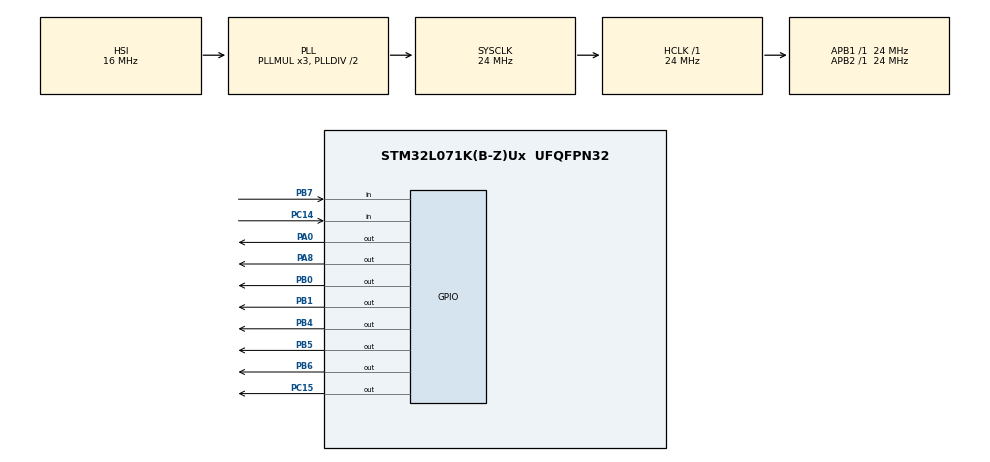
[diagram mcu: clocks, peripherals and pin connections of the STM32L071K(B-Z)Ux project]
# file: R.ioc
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Mcu.Family=STM32L0
Mcu.Name=STM32L071K(B-Z)Ux
Mcu.Package=UFQFPN32
PA0.GPIO_PuPd=GPIO_PULLDOWN
PA0.PinState=GPIO_PIN_RESET
PA0.Signal=GPIO_Output
PA8.Signal=GPIO_Output
PB0.Signal=GPIO_Output
PB1.Signal=GPIO_Output
PB4.Signal=GPIO_Output
PB5.Signal=GPIO_Output
PB6.Signal=GPIO_Output
PB7.Signal=GPIO_Input
PC14-OSC32_IN.Signal=GPIO_Input
PC15-OSC32_OUT.Signal=GPIO_Output
ProjectManager.HeapSize=0x200
ProjectManager.StackSize=0x400
ProjectManager.TargetToolchain=MDK-ARM V5
RCC.AHBFreq_Value=24000000
RCC.APB1Freq_Value=24000000
RCC.APB1TimFreq_Value=24000000
RCC.APB2Freq_Value=24000000
RCC.APB2TimFreq_Value=24000000
RCC.HCLKFreq_Value=24000000
RCC.HSI16_VALUE=16000000
RCC.HSI_VALUE=16000000
RCC.LSE_VALUE=32768
RCC.MSI_VALUE=2097000
RCC.SYSCLKFreq_VALUE=24000000
RCC.SYSCLKSource=RCC_SYSCLKSOURCE_PLLCLK
RCC.VCOOutputFreq_Value=48000000
RTC.Date=10
RTC.Format=RTC_FORMAT_BIN
RTC.Hours=10
RTC.Minutes=10
RTC.Month=RTC_MONTH_OCTOBER
RTC.Seconds=10
RTC.WeekDay=RTC_WEEKDAY_WEDNESDAY
RTC.Year=1
VP_RTC_VS_RTC_Activate.Mode=RTC_Enabled
VP_RTC_VS_RTC_Calendar.Mode=RTC_Calendar
board=custom

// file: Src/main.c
/* USER CODE BEGIN Header */
/**
  ******************************************************************************
  * @file           : main.c
  * @brief          : Main program body
  ******************************************************************************
  * @attention
  *
  * <h2><center>&copy; Copyright (c) 2019 STMicroelectronics.
  * All rights reserved.</center></h2>
  *
  * This software component is licensed by ST under BSD 3-Clause license,
  * the "License"; You may not use this file except in compliance with the
  * License. You may obtain a copy of the License at:
  *                        opensource.org/licenses/BSD-3-Clause
  *
  ******************************************************************************
  */
/* USER CODE END Header */

#include "main.h"

RTC_HandleTypeDef hrtc;

void SystemClock_Config(void);
static void MX_GPIO_Init(void);
static void MX_RTC_Init(void);

int main(void)
{

    /* MCU Configuration--------------------------------------------------------*/

    /* Reset of all peripherals, Initializes the Flash interface and the Systick. */
    HAL_Init();

    /* Configure the system clock */
    SystemClock_Config();

    /* Initialize all configured peripherals */
    MX_GPIO_Init();
    MX_RTC_Init();
    /* USER CODE BEGIN 2 */
    Task_BrdInit();

    /* USER CODE END 2 */

    /* Infinite loop */
    while (1)
    {

        /* USER CODE BEGIN 3 */
        Task_Main();
    }
    /* USER CODE END 3 */
}

void SystemClock_Config(void)
{
    RCC_OscInitTypeDef RCC_OscInitStruct = {0};
    RCC_ClkInitTypeDef RCC_ClkInitStruct = {0};
    RCC_PeriphCLKInitTypeDef PeriphClkInit = {0};

    /** Configure the main internal regulator output voltage
    */
    __HAL_PWR_VOLTAGESCALING_CONFIG(PWR_REGULATOR_VOLTAGE_SCALE1);
    /** Initializes the CPU, AHB and APB busses clocks
    */
    RCC_OscInitStruct.OscillatorType = RCC_OSCILLATORTYPE_HSI | RCC_OSCILLATORTYPE_LSI;
    RCC_OscInitStruct.HSIState = RCC_HSI_ON;
    RCC_OscInitStruct.HSICalibrationValue = RCC_HSICALIBRATION_DEFAULT;
    RCC_OscInitStruct.LSIState = RCC_LSI_ON;
    RCC_OscInitStruct.PLL.PLLState = RCC_PLL_ON;
    RCC_OscInitStruct.PLL.PLLSource = RCC_PLLSOURCE_HSI;
    RCC_OscInitStruct.PLL.PLLMUL = RCC_PLLMUL_3;
    RCC_OscInitStruct.PLL.PLLDIV = RCC_PLLDIV_2;
    if (HAL_RCC_OscConfig(&RCC_OscInitStruct) != HAL_OK)
    {
        Error_Handler();
    }
    /** Initializes the CPU, AHB and APB busses clocks
    */
    RCC_ClkInitStruct.ClockType = RCC_CLOCKTYPE_HCLK | RCC_CLOCKTYPE_SYSCLK
                                  | RCC_CLOCKTYPE_PCLK1 | RCC_CLOCKTYPE_PCLK2;
    RCC_ClkInitStruct.SYSCLKSource = RCC_SYSCLKSOURCE_PLLCLK;
    RCC_ClkInitStruct.AHBCLKDivider = RCC_SYSCLK_DIV1;
    RCC_ClkInitStruct.APB1CLKDivider = RCC_HCLK_DIV1;
    RCC_ClkInitStruct.APB2CLKDivider = RCC_HCLK_DIV1;

    if (HAL_RCC_ClockConfig(&RCC_ClkInitStruct, FLASH_LATENCY_1) != HAL_OK)
    {
        Error_Handler();
    }
    PeriphClkInit.PeriphClockSelection = RCC_PERIPHCLK_RTC;
    PeriphClkInit.RTCClockSelection = RCC_RTCCLKSOURCE_LSI;
    if (HAL_RCCEx_PeriphCLKConfig(&PeriphClkInit) != HAL_OK)
    {
        Error_Handler();
    }
}

static void MX_RTC_Init(void)
{

    RTC_TimeTypeDef sTime = {0};
    RTC_DateTypeDef sDate = {0};

    /** Initialize RTC Only
    */
    hrtc.Instance = RTC;
    hrtc.Init.HourFormat = RTC_HOURFORMAT_24;
    hrtc.Init.AsynchPrediv = 127;
    hrtc.Init.SynchPrediv = 255;
    hrtc.Init.OutPut = RTC_OUTPUT_DISABLE;
    hrtc.Init.OutPutRemap = RTC_OUTPUT_REMAP_NONE;
    hrtc.Init.OutPutPolarity = RTC_OUTPUT_POLARITY_HIGH;
    hrtc.Init.OutPutType = RTC_OUTPUT_TYPE_OPENDRAIN;
    if (HAL_RTC_Init(&hrtc) != HAL_OK)
    {
        Error_Handler();
    }

    /** Initialize RTC and set the Time and Date
    */
    sTime.Hours = 10;
    sTime.Minutes = 10;
    sTime.Seconds = 10;
    sTime.DayLightSaving = RTC_DAYLIGHTSAVING_NONE;
    sTime.StoreOperation = RTC_STOREOPERATION_RESET;
    if (HAL_RTC_SetTime(&hrtc, &sTime, RTC_FORMAT_BIN) != HAL_OK)
    {
        Error_Handler();
    }
    sDate.WeekDay = RTC_WEEKDAY_WEDNESDAY;
    sDate.Month = RTC_MONTH_OCTOBER;
    sDate.Date = 10;
    sDate.Year = 1;

    if (HAL_RTC_SetDate(&hrtc, &sDate, RTC_FORMAT_BIN) != HAL_OK)
    {
        Error_Handler();
    }

}

static void MX_GPIO_Init(void)
{
    GPIO_InitTypeDef GPIO_InitStruct = {0};

    /* GPIO Ports Clock Enable */
    __HAL_RCC_GPIOC_CLK_ENABLE();
    __HAL_RCC_GPIOA_CLK_ENABLE();
    __HAL_RCC_GPIOB_CLK_ENABLE();

    /*Configure GPIO pin Output Level */
    HAL_GPIO_WritePin(GPIOC, GPIO_PIN_15, GPIO_PIN_RESET);

    /*Configure GPIO pin Output Level */
    HAL_GPIO_WritePin(GPIOA, GPIO_PIN_0 | GPIO_PIN_8, GPIO_PIN_RESET);

    /*Configure GPIO pin Output Level */
    HAL_GPIO_WritePin(GPIOB, GPIO_PIN_0 | GPIO_PIN_1 | GPIO_PIN_4 | GPIO_PIN_5
                      | GPIO_PIN_6, GPIO_PIN_RESET);

    /*Configure GPIO pin : PC14 */
    GPIO_InitStruct.Pin = GPIO_PIN_14;
    GPIO_InitStruct.Mode = GPIO_MODE_INPUT;
    GPIO_InitStruct.Pull = GPIO_NOPULL;
    HAL_GPIO_Init(GPIOC, &GPIO_InitStruct);

    /*Configure GPIO pin : PC15 */
    GPIO_InitStruct.Pin = GPIO_PIN_15;
    GPIO_InitStruct.Mode = GPIO_MODE_OUTPUT_PP;
    GPIO_InitStruct.Pull = GPIO_NOPULL;
    GPIO_InitStruct.Speed = GPIO_SPEED_FREQ_LOW;
    HAL_GPIO_Init(GPIOC, &GPIO_InitStruct);

    /*Configure GPIO pin : PA0 */
    GPIO_InitStruct.Pin = GPIO_PIN_0;
    GPIO_InitStruct.Mode = GPIO_MODE_OUTPUT_PP;
    GPIO_InitStruct.Pull = GPIO_PULLDOWN;
    GPIO_InitStruct.Speed = GPIO_SPEED_FREQ_LOW;
    HAL_GPIO_Init(GPIOA, &GPIO_InitStruct);

    /*Configure GPIO pins : PB0 PB1 PB4 PB5
                             PB6 */
    GPIO_InitStruct.Pin = GPIO_PIN_0 | GPIO_PIN_1 | GPIO_PIN_4 | GPIO_PIN_5
                          | GPIO_PIN_6;
    GPIO_InitStruct.Mode = GPIO_MODE_OUTPUT_PP;
    GPIO_InitStruct.Pull = GPIO_NOPULL;
    GPIO_InitStruct.Speed = GPIO_SPEED_FREQ_LOW;
    HAL_GPIO_Init(GPIOB, &GPIO_InitStruct);

    /*Configure GPIO pin : PA8 */
    GPIO_InitStruct.Pin = GPIO_PIN_8;
    GPIO_InitStruct.Mode = GPIO_MODE_OUTPUT_PP;
    GPIO_InitStruct.Pull = GPIO_NOPULL;
    GPIO_InitStruct.Speed = GPIO_SPEED_FREQ_LOW;
    HAL_GPIO_Init(GPIOA, &GPIO_InitStruct);

    /*Configure GPIO pin : PB7 */
    GPIO_InitStruct.Pin = GPIO_PIN_7;
    GPIO_InitStruct.Mode = GPIO_MODE_INPUT;
    GPIO_InitStruct.Pull = GPIO_NOPULL;
    HAL_GPIO_Init(GPIOB, &GPIO_InitStruct);

}

void Error_Handler(void)
{
}

/************************ (C) COPYRIGHT STMicroelectronics *****END OF FILE****/
